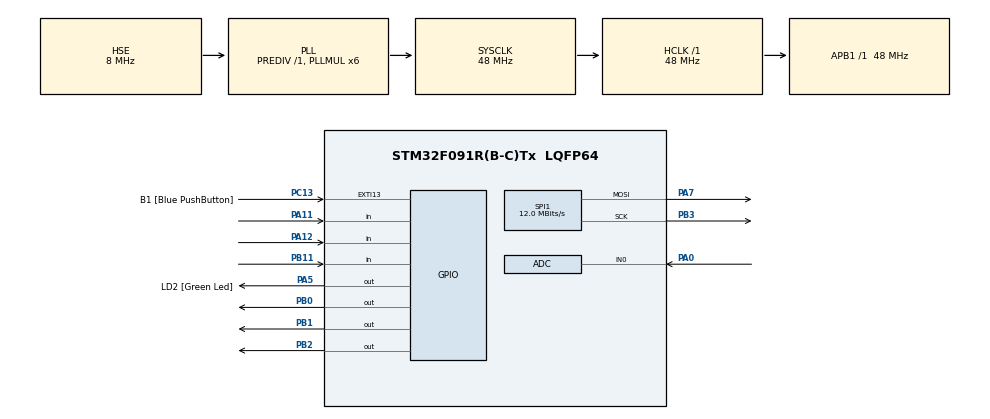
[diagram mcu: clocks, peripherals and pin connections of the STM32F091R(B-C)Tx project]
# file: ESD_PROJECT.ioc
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ADC.ExternalTrigConv=ADC_EXTERNALTRIGCONV_T3_TRGO
Dma.ADC.1.Direction=DMA_PERIPH_TO_MEMORY
Dma.ADC.1.Instance=DMA1_Channel1
Dma.ADC.1.MemDataAlignment=DMA_MDATAALIGN_HALFWORD
Dma.ADC.1.MemInc=DMA_MINC_ENABLE
Dma.ADC.1.Mode=DMA_NORMAL
Dma.ADC.1.PeriphDataAlignment=DMA_PDATAALIGN_HALFWORD
Dma.ADC.1.PeriphInc=DMA_PINC_DISABLE
Dma.ADC.1.Priority=DMA_PRIORITY_LOW
Dma.Request0=SPI1_TX
Dma.Request1=ADC
Dma.SPI1_TX.0.Direction=DMA_MEMORY_TO_PERIPH
Dma.SPI1_TX.0.Instance=DMA1_Channel3
Dma.SPI1_TX.0.MemDataAlignment=DMA_MDATAALIGN_BYTE
Dma.SPI1_TX.0.MemInc=DMA_MINC_ENABLE
Dma.SPI1_TX.0.Mode=DMA_NORMAL
Dma.SPI1_TX.0.PeriphDataAlignment=DMA_PDATAALIGN_BYTE
Dma.SPI1_TX.0.PeriphInc=DMA_PINC_DISABLE
Dma.SPI1_TX.0.Priority=DMA_PRIORITY_LOW
Mcu.Family=STM32F0
Mcu.Name=STM32F091R(B-C)Tx
Mcu.Package=LQFP64
NVIC.DMA1_Ch1_IRQn=true\:0\:0\:false\:false\:true\:false\:true\:true
NVIC.DMA1_Ch2_3_DMA2_Ch1_2_IRQn=true\:0\:0\:false\:false\:true\:false\:true\:true
PA0.Mode=IN0
PA0.Signal=ADC_IN0
PA11.GPIO_PuPd=GPIO_PULLUP
PA11.Signal=GPIO_Input
PA12.GPIO_PuPd=GPIO_PULLUP
PA12.Signal=GPIO_Input
PA13.GPIO_Label=TMS
PA13.Mode=Serial_Wire
PA13.Signal=SYS_SWDIO
PA14.GPIO_Label=TCK
PA14.Mode=Serial_Wire
PA14.Signal=SYS_SWCLK
PA5.GPIO_Label=LD2 [Green Led]
PA5.GPIO_Mode=GPIO_MODE_OUTPUT_PP
PA5.GPIO_PuPd=GPIO_NOPULL
PA5.GPIO_Speed=GPIO_SPEED_FREQ_LOW
PA5.Signal=GPIO_Output
PA7.Mode=TX_Only_Simplex_Unidirect_Master
PA7.Signal=SPI1_MOSI
PB0.Signal=GPIO_Output
PB1.Signal=GPIO_Output
PB11.GPIO_PuPd=GPIO_PULLUP
PB11.Signal=GPIO_Input
PB2.Signal=GPIO_Output
PB3.Mode=TX_Only_Simplex_Unidirect_Master
PB3.Signal=SPI1_SCK
PC13.GPIO_Label=B1 [Blue PushButton]
PC13.GPIO_ModeDefaultEXTI=GPIO_MODE_IT_FALLING
PC13.Signal=GPXTI13
PC14OSC32_IN.Signal=RCC_OSC32_IN
PC15OSC32_OUT.Signal=RCC_OSC32_OUT
PF0-OSC_IN.Mode=HSE-External-Oscillator
PF0-OSC_IN.Signal=RCC_OSC_IN
PF1-OSC_OUT.Mode=HSE-External-Oscillator
PF1-OSC_OUT.Signal=RCC_OSC_OUT
ProjectManager.HeapSize=0x200
ProjectManager.StackSize=0x400
ProjectManager.TargetToolchain=STM32CubeIDE
RCC.AHBFreq_Value=48000000
RCC.APB1Freq_Value=48000000
RCC.APB1TimFreq_Value=48000000
RCC.FLatency-AdvancedSettings=FLASH_LATENCY_1
RCC.HCLKFreq_Value=48000000
RCC.PLLMUL=RCC_PLL_MUL6
RCC.PREFETCH_ENABLE-AdvancedSettings=1
RCC.SYSCLKFreq_VALUE=48000000
RCC.SYSCLKSource=RCC_SYSCLKSOURCE_PLLCLK
SPI1.BaudRatePrescaler=SPI_BAUDRATEPRESCALER_4
SPI1.CalculateBaudRate=12.0 MBits/s
SPI1.DataSize=SPI_DATASIZE_8BIT
SPI1.Direction=SPI_DIRECTION_2LINES
SPI1.Mode=SPI_MODE_MASTER
SPI1.VirtualType=VM_MASTER
TIM3.Period=999
TIM3.Prescaler=4799
TIM3.TIM_MasterOutputTrigger=TIM_TRGO_UPDATE
TIM3.TIM_MasterSlaveMode=TIM_MASTERSLAVEMODE_DISABLE
VP_TIM3_VS_ClockSourceINT.Mode=Internal
board=NUCLEO-F091RC

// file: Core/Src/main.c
/* USER CODE BEGIN Header */
/**
  ******************************************************************************
  * @file           : main.c
  * @brief          : Main program body
  ******************************************************************************
  * @attention
  *
  * Copyright (c) 2024 STMicroelectronics.
  * All rights reserved.
  *
  * This software is licensed under terms that can be found in the LICENSE file
  * in the root directory of this software component.
  * If no LICENSE file comes with this software, it is provided AS-IS.
  *
  ******************************************************************************
  */
/* USER CODE END Header */
#include "main.h"
#include "dso.h"
#include "ui.h"
#include <stm32f0xx.h>
/* USER CODE BEGIN Includes */
#include "ILI9341_STM32_Driver.h"
#include "ILI9341_GFX.h"
/* USER CODE END Includes */

ADC_HandleTypeDef hadc;
DMA_HandleTypeDef hdma_adc;

SPI_HandleTypeDef hspi1;
DMA_HandleTypeDef hdma_spi1_tx;

TIM_HandleTypeDef htim3;

void SystemClock_Config(void);
static void MX_GPIO_Init(void);
static void MX_DMA_Init(void);
static void MX_SPI1_Init(void);
static void MX_ADC_Init(void);
static void MX_TIM3_Init(void);

int main(void)
{

  /* MCU Configuration--------------------------------------------------------*/

  /* Reset of all peripherals, Initializes the Flash interface and the Systick. */
  HAL_Init();

  /* Configure the system clock */
  SystemClock_Config();

  /* Initialize all configured peripherals */
  MX_GPIO_Init();
  MX_DMA_Init();
  MX_SPI1_Init();
  MX_ADC_Init();
  MX_TIM3_Init();
  /* USER CODE BEGIN 2 */
  DSO_Init();
//  autoCal();
  /* Infinite loop */
  /* USER CODE BEGIN WHILE */
  while (1)
  {
	  DSO_Loop();
  }
  /* USER CODE END 3 */
}

void SystemClock_Config(void)
{
    RCC_OscInitTypeDef RCC_OscInitStruct = {0};
    RCC_ClkInitTypeDef RCC_ClkInitStruct = {0};

    /** Configure the main internal regulator output voltage */
    HAL_RCC_OscConfig(&RCC_OscInitStruct);

    /** Initializes the RCC Oscillators according to the specified parameters */
    RCC_OscInitStruct.OscillatorType = RCC_OSCILLATORTYPE_HSE;  // Enable HSE
    RCC_OscInitStruct.HSEState = RCC_HSE_ON;                   // Turn on HSE
    RCC_OscInitStruct.PLL.PLLState = RCC_PLL_ON;
    RCC_OscInitStruct.PLL.PLLSource = RCC_PLLSOURCE_HSE;       // Use HSE as PLL source
    RCC_OscInitStruct.PLL.PREDIV = RCC_PREDIV_DIV1;            // No pre-divider
    RCC_OscInitStruct.PLL.PLLMUL = RCC_PLL_MUL6;               // 8 MHz x 6 = 48 MHz
    if (HAL_RCC_OscConfig(&RCC_OscInitStruct) != HAL_OK)
    {
        Error_Handler();
    }

    /** Initializes the CPU, AHB and APB buses clocks */
    RCC_ClkInitStruct.ClockType = RCC_CLOCKTYPE_HCLK | RCC_CLOCKTYPE_SYSCLK | RCC_CLOCKTYPE_PCLK1;
    RCC_ClkInitStruct.SYSCLKSource = RCC_SYSCLKSOURCE_PLLCLK;  // Use PLL output as SYSCLK
    RCC_ClkInitStruct.AHBCLKDivider = RCC_SYSCLK_DIV1;         // AHB = SYSCLK
    RCC_ClkInitStruct.APB1CLKDivider = RCC_HCLK_DIV1;          // APB1 = HCLK

    if (HAL_RCC_ClockConfig(&RCC_ClkInitStruct, FLASH_LATENCY_1) != HAL_OK)
    {
        Error_Handler();
    }
}

static void MX_ADC_Init(void)
{

  ADC_ChannelConfTypeDef sConfig = {0};

  /** Configure the global features of the ADC (Clock, Resolution, Data Alignment and number of conversion)
  */
  hadc.Instance = ADC1;
  hadc.Init.ClockPrescaler = ADC_CLOCK_ASYNC_DIV1;
  hadc.Init.Resolution = ADC_RESOLUTION_12B;
  hadc.Init.DataAlign = ADC_DATAALIGN_RIGHT;
  hadc.Init.ScanConvMode = ADC_SCAN_DIRECTION_FORWARD;
  hadc.Init.EOCSelection = ADC_EOC_SINGLE_CONV;
  hadc.Init.LowPowerAutoWait = DISABLE;
  hadc.Init.LowPowerAutoPowerOff = DISABLE;
  hadc.Init.ContinuousConvMode = DISABLE;
  hadc.Init.DiscontinuousConvMode = DISABLE;
  hadc.Init.ExternalTrigConv = ADC_EXTERNALTRIGCONV_T3_TRGO;
  hadc.Init.ExternalTrigConvEdge = ADC_EXTERNALTRIGCONVEDGE_RISING;
  hadc.Init.DMAContinuousRequests = DISABLE;
  hadc.Init.Overrun = ADC_OVR_DATA_PRESERVED;
  if (HAL_ADC_Init(&hadc) != HAL_OK)
  {
    Error_Handler();
  }

  /** Configure for the selected ADC regular channel to be converted.
  */
  sConfig.Channel = ADC_CHANNEL_0;
  sConfig.Rank = ADC_RANK_CHANNEL_NUMBER;
  sConfig.SamplingTime = ADC_SAMPLETIME_1CYCLE_5;
  if (HAL_ADC_ConfigChannel(&hadc, &sConfig) != HAL_OK)
  {
    Error_Handler();
  }

}

static void MX_SPI1_Init(void)
{

  /* SPI1 parameter configuration*/
  hspi1.Instance = SPI1;
  hspi1.Init.Mode = SPI_MODE_MASTER;
  hspi1.Init.Direction = SPI_DIRECTION_2LINES;
  hspi1.Init.DataSize = SPI_DATASIZE_8BIT;
  hspi1.Init.CLKPolarity = SPI_POLARITY_LOW;
  hspi1.Init.CLKPhase = SPI_PHASE_1EDGE;
  hspi1.Init.NSS = SPI_NSS_SOFT;
  hspi1.Init.BaudRatePrescaler = SPI_BAUDRATEPRESCALER_2;
  hspi1.Init.FirstBit = SPI_FIRSTBIT_MSB;
  hspi1.Init.TIMode = SPI_TIMODE_DISABLE;
  hspi1.Init.CRCCalculation = SPI_CRCCALCULATION_DISABLE;
  hspi1.Init.CRCPolynomial = 7;
  hspi1.Init.CRCLength = SPI_CRC_LENGTH_DATASIZE;
  hspi1.Init.NSSPMode = SPI_NSS_PULSE_ENABLE;
  if (HAL_SPI_Init(&hspi1) != HAL_OK)
  {
    Error_Handler();
  }

}

static void MX_TIM3_Init(void)
{

  TIM_ClockConfigTypeDef sClockSourceConfig = {0};
  TIM_MasterConfigTypeDef sMasterConfig = {0};

  htim3.Instance = TIM3;
  htim3.Init.Prescaler = 0;
  htim3.Init.CounterMode = TIM_COUNTERMODE_UP;
  htim3.Init.Period = 65535;
  htim3.Init.ClockDivision = TIM_CLOCKDIVISION_DIV1;
  htim3.Init.AutoReloadPreload = TIM_AUTORELOAD_PRELOAD_DISABLE;
  if (HAL_TIM_Base_Init(&htim3) != HAL_OK)
  {
    Error_Handler();
  }
  sClockSourceConfig.ClockSource = TIM_CLOCKSOURCE_INTERNAL;
  if (HAL_TIM_ConfigClockSource(&htim3, &sClockSourceConfig) != HAL_OK)
  {
    Error_Handler();
  }
  sMasterConfig.MasterOutputTrigger = TIM_TRGO_UPDATE;
  sMasterConfig.MasterSlaveMode = TIM_MASTERSLAVEMODE_DISABLE;
  if (HAL_TIMEx_MasterConfigSynchronization(&htim3, &sMasterConfig) != HAL_OK)
  {
    Error_Handler();
  }

}

static void MX_DMA_Init(void)
{

  /* DMA controller clock enable */
  __HAL_RCC_DMA1_CLK_ENABLE();

  /* DMA interrupt init */
  /* DMA1_Ch1_IRQn interrupt configuration */
  HAL_NVIC_SetPriority(DMA1_Ch1_IRQn, 0, 0);
  HAL_NVIC_EnableIRQ(DMA1_Ch1_IRQn);
  /* DMA1_Ch2_3_DMA2_Ch1_2_IRQn interrupt configuration */
  HAL_NVIC_SetPriority(DMA1_Ch2_3_DMA2_Ch1_2_IRQn, 0, 0);
  HAL_NVIC_EnableIRQ(DMA1_Ch2_3_DMA2_Ch1_2_IRQn);

}

static void MX_GPIO_Init(void)
{
	  GPIO_InitTypeDef GPIO_InitStruct = {0};

	  /* GPIO Ports Clock Enable */
	  __HAL_RCC_GPIOC_CLK_ENABLE();
	  __HAL_RCC_GPIOF_CLK_ENABLE();
	  __HAL_RCC_GPIOA_CLK_ENABLE();
	  __HAL_RCC_GPIOB_CLK_ENABLE();

	  /*Configure GPIO pin Output Level */
	  HAL_GPIO_WritePin(LD2_GPIO_Port, LD2_Pin, GPIO_PIN_RESET);

	  /*Configure GPIO pin Output Level */
	  HAL_GPIO_WritePin(GPIOB, GPIO_PIN_0|GPIO_PIN_1|GPIO_PIN_2, GPIO_PIN_RESET);

	  /*Configure GPIO pin : B1_Pin */
	  GPIO_InitStruct.Pin = B1_Pin;
	  GPIO_InitStruct.Mode = GPIO_MODE_IT_FALLING;
	  GPIO_InitStruct.Pull = GPIO_NOPULL;
	  HAL_GPIO_Init(B1_GPIO_Port, &GPIO_InitStruct);

	  /*Configure GPIO pin : LD2_Pin */
	  GPIO_InitStruct.Pin = LD2_Pin;
	  GPIO_InitStruct.Mode = GPIO_MODE_OUTPUT_PP;
	  GPIO_InitStruct.Pull = GPIO_NOPULL;
	  GPIO_InitStruct.Speed = GPIO_SPEED_FREQ_LOW;
	  HAL_GPIO_Init(LD2_GPIO_Port, &GPIO_InitStruct);

	  /*Configure GPIO pins : PB0 PB1 PB2 */
	  GPIO_InitStruct.Pin = GPIO_PIN_0|GPIO_PIN_1|GPIO_PIN_2;
	  GPIO_InitStruct.Mode = GPIO_MODE_OUTPUT_PP;
	  GPIO_InitStruct.Pull = GPIO_NOPULL;
	  GPIO_InitStruct.Speed = GPIO_SPEED_FREQ_LOW;
	  HAL_GPIO_Init(GPIOB, &GPIO_InitStruct);

	  /* Configure GPIO pin : PB13 */
	  GPIO_InitStruct.Pin = GPIO_PIN_13;
	  GPIO_InitStruct.Mode = GPIO_MODE_IT_FALLING; // Interrupt mode
	  GPIO_InitStruct.Pull = GPIO_PULLUP;
	  HAL_GPIO_Init(GPIOB, &GPIO_InitStruct);

	  /* Configure GPIO pins : PA11 PA12 */
	  GPIO_InitStruct.Pin = GPIO_PIN_11 | GPIO_PIN_12;
	  GPIO_InitStruct.Mode = GPIO_MODE_IT_FALLING; // Interrupt mode
	  GPIO_InitStruct.Pull = GPIO_PULLUP;
	  HAL_GPIO_Init(GPIOA, &GPIO_InitStruct);

	  /* Enable and set EXTI interrupt priority */
	  HAL_NVIC_SetPriority(EXTI4_15_IRQn, 2, 0); // Priority level 2
	  HAL_NVIC_EnableIRQ(EXTI4_15_IRQn);

}

void Error_Handler(void)
{
  __disable_irq();
  while (1)
  {
  }
}
